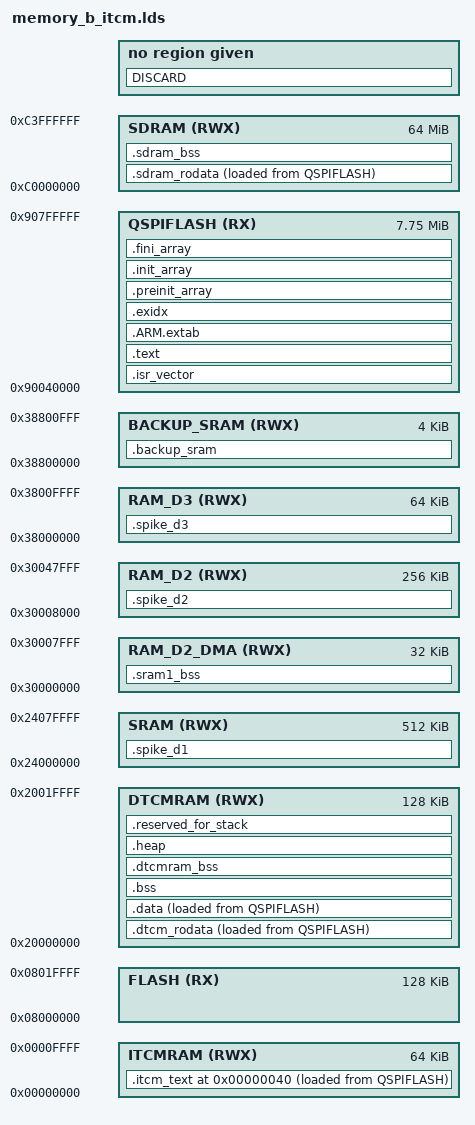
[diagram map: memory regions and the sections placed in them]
/* Option BI of the texture load spike (../README.md): option B (memory_b.lds, derived from libDaisy
 * core/STM32H750IB_qspi.lds at the pinned libDaisy f715e48) plus the hot DSP code of option AI in ITCM
 * and the hot lookup tables in DTCM. Changes against memory_b.lds: sections .itcm_text (same patterns
 * as memory_a_itcm.lds), .dtcm_rodata and .sdram_rodata (the synth wavetable, from 0.4.0), all loaded
 * from QSPI and copied at start-up (src/main.cpp).
 * All are placed before .text, whose *(.text*) and *(.rodata*) would otherwise collect them.
 * Everything else as in memory_b.lds.
 */
/* Generated by LinkerScriptGenerator [http://visualgdb.com/tools/LinkerScriptGenerator]
 * Target: STM32H750IB
 * The file is provided under the BSD license.
 * yeah okay but i also modified it a lot so like, give me some credit too mr BSD
 */

ENTRY(Reset_Handler)

MEMORY
{
	FLASH       (RX)  : ORIGIN = 0x08000000, LENGTH = 128K
	DTCMRAM     (RWX) : ORIGIN = 0x20000000, LENGTH = 128K
	SRAM        (RWX) : ORIGIN = 0x24000000, LENGTH = 512K
	RAM_D2_DMA  (RWX) : ORIGIN = 0x30000000, LENGTH = 32K
	RAM_D2      (RWX) : ORIGIN = 0x30008000, LENGTH = 256K
	RAM_D3      (RWX) : ORIGIN = 0x38000000, LENGTH = 64K
	BACKUP_SRAM (RWX) : ORIGIN = 0x38800000, LENGTH = 4K
	ITCMRAM     (RWX) : ORIGIN = 0x00000000, LENGTH = 64K
	SDRAM       (RWX) : ORIGIN = 0xc0000000, LENGTH = 64M
	QSPIFLASH   (RX)  : ORIGIN = 0x90040000, LENGTH = 7936K
}

_estack = 0x20020000;

SECTIONS
{
	.isr_vector :
	{
		. = ALIGN(4);
		KEEP(*(.isr_vector))
		. = ALIGN(4);
	} > QSPIFLASH

	/* Texture load spike, BI: hot DSP code in ITCM, copied at start-up (src/main.cpp). Starts at
	   0x40 so that no function has address 0. Calls from QSPI reach it through veneers. */
	.itcm_text 0x00000040 : ALIGN(4)
	{
		_sitcm_text = .;
		*(.text._ZN5beads17GranularProcessorILNS_10ResolutionE2ELi192000ELi1EE*)
		*(.text._ZN5beads17GranularProcessorILNS_10ResolutionE0ELi384000ELi2EE*)
		*(.text._ZN5beads9Processor7Process*)
		*(.text._ZN5beads13MultitapDelay6RenderINS_9DelayLineILNS_10ResolutionE2ELi192000ELi2E*)
		*(.text._ZN5beads15DelayController6Render*)
		*(.text._ZN5beads15DelayController14RenderInternal*)
		*(.text._ZN6stmlib19SampleRateConverter*)
		*(.text._ZN5beads6Reverb7Process*)
		*(.text._ZNK5beads19RandomizedParameter5value*)
		*(.text._ZN5beads14GranularPlayer*)
		*(.text._ZNSt3_V28__rotate*)
		*(.text._ZSt13__adjust_heap*)
		*(.text._ZN5beads5Grain7Compare*)
		*(.text._ZN5beads16TriggerGenerator6Render*)
		*(.text._ZN5beads16TriggerGenerator16RenderPulseTrain*)
		*(.text._ZN5beads5Synth6Render*)
		*(.text._ZN12_GLOBAL__N_113AudioCallback*)
		*(.text._ZN5spike*)
		. = ALIGN(4);
		_eitcm_text = .;
	} > ITCMRAM AT > QSPIFLASH
	_siitcm_text = LOADADDR(.itcm_text);

	/* Texture load spike, BI: the lookup tables the hot code reads (sine oscillator, pitch ratio),
	   so that no D-cache refill of them goes to QSPI. Copied at start-up like .itcm_text. */
	.dtcm_rodata : ALIGN(4)
	{
		_sdtcm_rodata = .;
		*(.rodata._ZN5beads8lut_sineE)
		*(.rodata._ZN6stmlib20lut_pitch_ratio_highE)
		*(.rodata._ZN6stmlib19lut_pitch_ratio_lowE)
		. = ALIGN(4);
		_edtcm_rodata = .;
	} > DTCMRAM AT > QSPIFLASH
	_sidtcm_rodata = LOADADDR(.dtcm_rodata);

	/* Texture load spike, BI from 0.4.0: the 99 KB wavetable of the synth mode, which fits neither ITCM nor
	   DTCM, in cached SDRAM instead of QSPI. SDRAM works only after hw.Init(), so main() copies it there,
	   before the engine starts; nothing reads it earlier. */
	.sdram_rodata : ALIGN(32)
	{
		_ssdram_rodata = .;
		*(.rodata._ZN5beads20wav_integrated_wavesE)
		. = ALIGN(4);
		_esdram_rodata = .;
	} > SDRAM AT > QSPIFLASH
	_sisdram_rodata = LOADADDR(.sdram_rodata);

	.text :
	{
		. = ALIGN(4);
		_stext = .;

		*(.text)
		*(.text*)
		*(.rodata)
		*(.rodata*)
		*(.glue_7)
		*(.glue_7t)
		KEEP(*(.init))
		KEEP(*(.fini))
		. = ALIGN(4);
		_etext = .;

	} > QSPIFLASH

	.ARM.extab :
	{
		. = ALIGN(4);
		*(.ARM.extab)
		*(.gnu.linkonce.armextab.*)
		. = ALIGN(4);
	} > QSPIFLASH

	.exidx :
	{
		. = ALIGN(4);
		PROVIDE(__exidx_start = .);
		*(.ARM.exidx*)
		. = ALIGN(4);
		PROVIDE(__exidx_end = .);
	} > QSPIFLASH

	.ARM.attributes 0 : { *(.ARM.attributes) }

	.preinit_array :
	{
		PROVIDE_HIDDEN(__preinit_array_start = .);
		KEEP(*(.preinit_array*))
		PROVIDE_HIDDEN(__preinit_array_end = .);
	} > QSPIFLASH

	.init_array :
	{
		PROVIDE_HIDDEN(__init_array_start = .);
		KEEP(*(SORT(.init_array.*)))
		KEEP(*(.init_array*))
		PROVIDE_HIDDEN(__init_array_end = .);
	} > QSPIFLASH

	.fini_array :
	{
		PROVIDE_HIDDEN(__fini_array_start = .);
		KEEP(*(.fini_array*))
		KEEP(*(SORT(.fini_array.*)))
		PROVIDE_HIDDEN(__fini_array_end = .);
	} > QSPIFLASH

	.sram1_bss (NOLOAD) :
	{
		. = ALIGN(4);
		_ssram1_bss = .;

		PROVIDE(__sram1_bss_start__ = _sram1_bss);
		*(.sram1_bss)
		*(.sram1_bss*)
		. = ALIGN(4);
		_esram1_bss = .;

		PROVIDE(__sram1_bss_end__ = _esram1_bss);
	} > RAM_D2_DMA

	.data :
	{
		. = ALIGN(4);
		_sdata = .;

		PROVIDE(__data_start__ = _sdata);
		*(.data)
		*(.data*)
		. = ALIGN(4);
		_edata = .;

		PROVIDE(__data_end__ = _edata);
	} > DTCMRAM AT > QSPIFLASH

	_sidata = LOADADDR(.data);

	.bss (NOLOAD) :
	{
		. = ALIGN(4);
		_sbss = .;

		PROVIDE(__bss_start__ = _sbss);
		*(.bss)
		*(.bss*)
		*(COMMON)
		. = ALIGN(4);
		_ebss = .;

		PROVIDE(__bss_end__ = _ebss);
	} > DTCMRAM

	.dtcmram_bss (NOLOAD) :
	{
		. = ALIGN(4);
		_sdtcmram_bss = .;

		PROVIDE(__dtcmram_bss_start__ = _sdtcmram_bss);
		*(.dtcmram_bss)
		*(.dtcmram_bss*)
		. = ALIGN(4);
		_edtcmram_bss = .;

		PROVIDE(__dtcmram_bss_end__ = _edtcmram_bss);
	} > DTCMRAM

	/*
	.sdram_text :
	{
		. = ALIGN(4);
		_ssdram_text = .;

		PROVIDE(__sdram_text_start = _ssdram_text);
		*(.sdram_text)
		*(.sdram_text*)
		. = ALIGN(4);
		_esdram_text = .;

		PROVIDE(__sdram_text_end = _esdram_text);
	} > SDRAM AT >FLASH
	_sisdram_text = LOADADDR(.sdram_text);
	*/

	.sdram_bss (NOLOAD) :
	{
		. = ALIGN(4);
		_ssdram_bss = .;

		PROVIDE(__sdram_bss_start = _ssdram_bss);
		*(.sdram_bss)
		*(.sdram_bss*)
		. = ALIGN(4);
		_esdram_bss = .;

		PROVIDE(__sdram_bss_end = _esdram_bss);
	} > SDRAM

	.backup_sram (NOLOAD) :
	{
		. = ALIGN(4);
		_sbackup_sram = .;

		PROVIDE(__backup_sram_start = _sbackup_sram);
		*(.backup_sram)
		*(.backup_sram*)
		. = ALIGN(4);
		_ebackup_sram = .;

		PROVIDE(__backup_sram_end = _ebackup_sram);
	} > BACKUP_SRAM


    /* .qspiflash_text :
	{
		. = ALIGN(4);
		_sqspiflash_text = .;

		PROVIDE(__qspiflash_text_start = _sqspiflash_text);
		*(.qspiflash_text)
		*(.qspiflash_text*)
		. = ALIGN(4);
		_eqspiflash_text = .;

		PROVIDE(__qspiflash_text_end = _eqspiflash_text);
	} > QSPIFLASH

	.qspiflash_data :
	{
		. = ALIGN(4);
		_sqspiflash_data = .;

		PROVIDE(__qspiflash_data_start = _sqspiflash_data);
		*(.qspiflash_data)
		*(.qspiflash_data*)
		. = ALIGN(4);
		_eqspiflash_data = .;

		PROVIDE(__qspiflash_data_end = _eqspiflash_data);
	} > QSPIFLASH

	.qspiflash_bss (NOLOAD) :
	{
		. = ALIGN(4);
		_sqspiflash_bss = .;

		PROVIDE(__qspiflash_bss_start = _sqspiflash_bss);
		*(.qspiflash_bss)
		*(.qspiflash_bss*)
		. = ALIGN(4);
		_eqspiflash_bss = .;

		PROVIDE(__qspiflash_bss_end = _eqspiflash_bss);
	} > QSPIFLASH */

	.heap (NOLOAD) :
	{
		. = ALIGN(4);
		PROVIDE(__heap_start__ = .);
		PROVIDE(__heap_start = .);
		KEEP(*(.heap))
		. = ALIGN(4);
		PROVIDE(__heap_end = .);
		PROVIDE(__heap_end__ = .);
	} > DTCMRAM

	PROVIDE(end = .);

	.reserved_for_stack (NOLOAD) :
	{
		. = ALIGN(4);
		PROVIDE(__reserved_for_stack_start__ = .);
		KEEP(*(.reserved_for_stack))
		. = ALIGN(4);
		PROVIDE(__reserved_for_stack_end__ = .);
	} > DTCMRAM

	/* Texture load spike, options B and BI: the Beads buffer layout (beads/beads.cc). */
	.spike_d1 (NOLOAD) : ALIGN(32) { *(.spike_d1) } > SRAM
	.spike_d2 (NOLOAD) : ALIGN(32) { *(.spike_d2) } > RAM_D2
	.spike_d3 (NOLOAD) : ALIGN(32) { *(.spike_d3) } > RAM_D3

    DISCARD :
    {
        libc.a ( * )
        libm.a ( * )
        libgcc.a ( * )
    }

}
/* Main stack: DTCM above .bss and .heap. */
ASSERT(end <= 0x20020000 - 16K, "DTCM stack reserve below 16 KiB")
